# ATSAMG55G19 register map
Vendor: Atmel; Series: SAMG55; File version: 0
CPU: CM4 r0p1, selectable endian, MPU, FPU, 4 interrupt priority bits
Registers are 32-bit, read-write, reset 0x0 unless marked. A register's access mark holds for its fields unless they carry their own. Offsets are from the block's base; [hi:lo] are bit positions; {n}, {i} and the like mark numbered series.

## MATRIX — AHB Bus Matrix
Base 0x400E0200
{0x0+4i} MATRIX_MCFG[{i}] (i=0..2) reset not defined — Master Configuration Register
  [2:0] ULBT — Undefined Length Burst Type
    0=UNLIMITED (No predicted end of burst is generated and therefore INCR bursts coming from this master cannot be broken.); 1=SINGLE (The undefined length burst is treated as a succession of single access allowing rearbitration at each beat of the INCR burst.); 2=4_BEAT (The undefined length burst is split into a 4-beat bursts allowing rearbitration at each 4-beat burst end.); 3=8_BEAT (The undefined length burst is split into 8-beat bursts allowing rearbitration at each 8-beat burst end.); 4=16_BEAT (The undefined length burst is split into 16-beat bursts allowing rearbitration at each 16-beat burst end.)
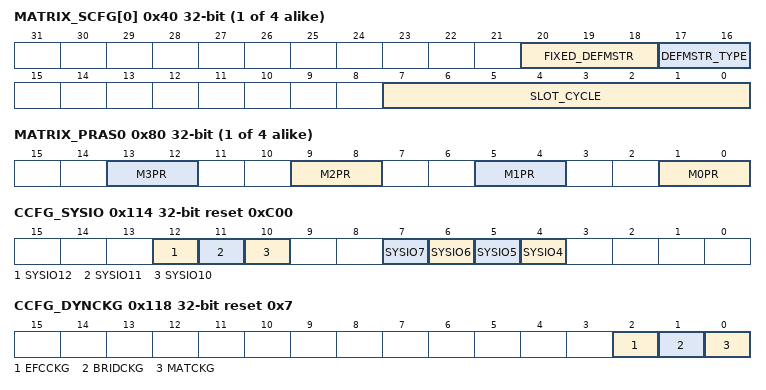
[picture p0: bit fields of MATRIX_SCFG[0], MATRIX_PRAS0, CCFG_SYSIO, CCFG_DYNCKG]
{0x40+4i} MATRIX_SCFG[{i}] (i=0..3) reset not defined — Slave Configuration Register
  [20:18] FIXED_DEFMSTR — Fixed Default Master
  [17:16] DEFMSTR_TYPE — Default Master Type
    0=NO_DEFAULT (At the end of current slave access, if no other master request is pending, the slave is disconnected from all masters.This results in having a one cycle latency for the first access of a burst transfer or for a single access.); 1=LAST (At the end of current slave access, if no other master request is pending, the slave stays connected to the last master having accessed it.This results in not having the one cycle latency when the last master tries to access the slave again.); 2=FIXED (At the end of the current slave access, if no other master request is pending, the slave connects to the fixed master the number that has been written in the FIXED_DEFMSTR field.This results in not having the one cycle latency when the fixed master tries to access the slave again.)
  [7:0] SLOT_CYCLE — Maximum Number of Allowed Cycles for a Burst
{0x80+8i} MATRIX_PRAS{i} (i=0..3) — Priority Register A for Slave {i}
  [4n+1:4n] M{n}PR (n=0..3) — Master {n} Priority
0x114 CCFG_SYSIO reset 0xC00 — System I/O Configuration Register
  [12] SYSIO12 — PB12 or ERASE Assignment
  [11] SYSIO11 — PA22 or DP Assignment
  [10] SYSIO10 — PA21 or DM Assignment
  [7] SYSIO7 — PB7 or TCK/SWCLK Assignment
  [6] SYSIO6 — PB6 or TMS/SWDIO Assignment
  [5] SYSIO5 — PB5 or TDO/TRACESWO Assignment
  [4] SYSIO4 — PB4 or TDI Assignment
0x118 CCFG_DYNCKG reset 0x7 — Dynamic Clock Gating Register
  [2] EFCCKG — EFC Dynamic Clock Gating Enable
  [1] BRIDCKG — Bridge Dynamic Clock Gating Enable
  [0] MATCKG — MATRIX Dynamic Clock Gating
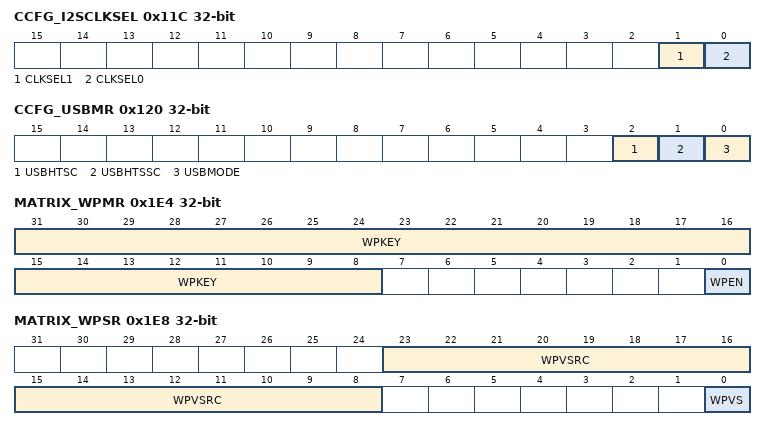
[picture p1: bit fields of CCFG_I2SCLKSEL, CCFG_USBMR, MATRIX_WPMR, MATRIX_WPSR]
0x11C CCFG_I2SCLKSEL — I2S Clock Source Selection Register
  [1] CLKSEL1 — I2S1 Clock Source
  [0] CLKSEL0 — I2S0 Clock Source
0x120 CCFG_USBMR — USB Management Register
  [2] USBHTSC — USB Host Transceiver Suspend Control
  [1] USBHTSSC — USB Transceiver Suspend Software Control
  [0] USBMODE — USB Mode Selection
0x1E4 MATRIX_WPMR — Write Protection Mode Register
  [31:8] WPKEY — Write Protection Key
    0x4D4154=PASSWD (Writing any other value in this field aborts the write operation of the WPEN bit. Always reads as 0.)
  [0] WPEN — Write Protection Enable
0x1E8 MATRIX_WPSR ro — Write Protection Status Register
  [23:8] WPVSRC — Write Protection Violation Source
  [0] WPVS — Write Protection Violation Status

## CHIPID — Chip Identifier
Base 0x400E0740; register names take the prefix CHIPID_
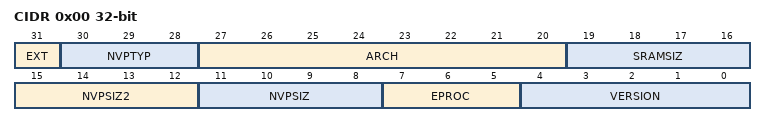
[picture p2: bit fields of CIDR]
0x00 CIDR ro reset not defined — Chip ID Register
  [31] EXT — Extension Flag
  [30:28] NVPTYP — Nonvolatile Program Memory Type
    0=ROM; 1=ROMLESS (ROMless or on-chip Flash); 2=FLASH (Embedded Flash Memory); 3=ROM_FLASH (ROM and Embedded Flash Memory- NVPSIZ is ROM size- NVPSIZ2 is Flash size); 4=SRAM (SRAM emulating ROM)
  [27:20] ARCH — Architecture Identifier
    68=SAMG55 (SAM G55 (49-lead version))
  [19:16] SRAMSIZ — Internal SRAM Size
    0=48K (48 Kbytes); 1=192K (192 Kbytes); 2=384K (384 Kbytes); 3=6K (6 Kbytes); 4=24K (24 Kbytes); 5=4K (4 Kbytes); 6=80K (80 Kbytes); 7=160K (160 Kbytes); 8=8K (8 Kbytes); 9=16K (16 Kbytes); 10=32K (32 Kbytes); 11=64K (64 Kbytes); 12=128K (128 Kbytes); 13=256K (256 Kbytes); 14=96K (96 Kbytes); 15=512K (512 Kbytes)
  [15:12] NVPSIZ2 — Second Nonvolatile Program Memory Size
    0=NONE; 1=8K (8 Kbytes); 2=16K (16 Kbytes); 3=32K (32 Kbytes); 5=64K (64 Kbytes); 7=128K (128 Kbytes); 9=256K (256 Kbytes); 10=512K (512 Kbytes); 12=1024K (1024 Kbytes); 14=2048K (2048 Kbytes)
  [11:8] NVPSIZ — Nonvolatile Program Memory Size
    0=NONE; 1=8K (8 Kbytes); 2=16K (16 Kbytes); 3=32K (32 Kbytes); 5=64K (64 Kbytes); 7=128K (128 Kbytes); 8=160K (160 Kbytes); 9=256K (256 Kbytes); 10=512K (512 Kbytes); 12=1024K (1024 Kbytes); 14=2048K (2048 Kbytes)
  [7:5] EPROC — Embedded Processor
    1=ARM946ES; 2=ARM7TDMI; 3=CM3 (Cortex-M3); 4=ARM920T; 5=ARM926EJS; 6=CA5 (Cortex-A5); 7=CM4 (Cortex-M4)
  [4:0] VERSION — Version of the Device
0x04 EXID ro reset not defined — Chip ID Extension Register
  [31:0] EXID — Chip ID Extension
